# MPU_R5SS1_CORE0_AXIS_MPU_R5SS1_CORE0_AXIS register map
Vendor: Texas Instruments
Peripheral module from a debugger description file (folder AM263).
Registers are 32-bit, read-only, reset 0x0 unless marked. A register's access mark holds for its fields unless they carry their own. Offsets are as the file gives them; lines under a group give offsets from that group; [hi:lo] are bit positions; {n}, {i} and the like mark numbered series; 'fields as' and 'values as' point back to an identical list; <NAME> marks a mode.

## MPU_R5SS1_CORE0_AXIS_MPU_R5SS1_CORE0_AXIS
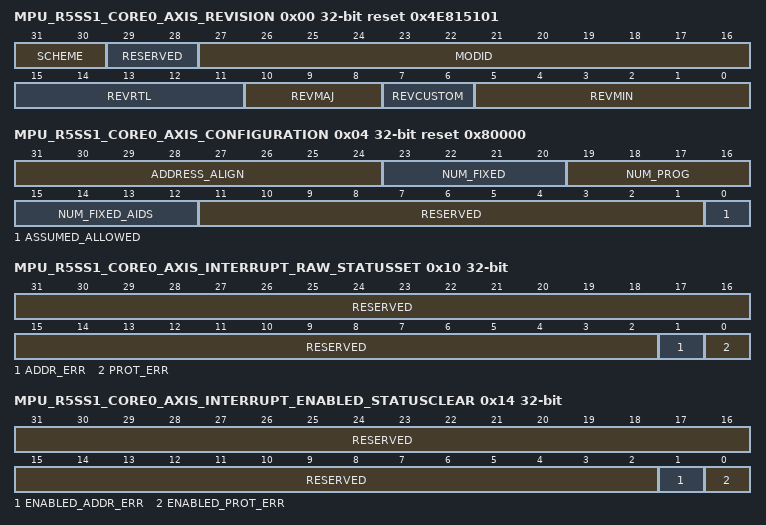
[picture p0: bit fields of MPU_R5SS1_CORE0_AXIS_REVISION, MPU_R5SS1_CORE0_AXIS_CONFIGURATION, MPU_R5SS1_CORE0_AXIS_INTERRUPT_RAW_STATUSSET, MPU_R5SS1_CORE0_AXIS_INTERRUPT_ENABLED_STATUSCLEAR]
0x00 MPU_R5SS1_CORE0_AXIS_REVISION reset 0x4E815101
  [31:30] SCHEME
  [29:28] RESERVED — Always read a s0. Writes have no affect.
  [27:16] MODID — Module ID field.
  [15:11] REVRTL — RTL revision.Will vary depending on release.
  [10:8] REVMAJ — Majo revision.
  [7:6] REVCUSTOM — Custom revision.
  [5:0] REVMIN — Minor revision.
0x04 MPU_R5SS1_CORE0_AXIS_CONFIGURATION reset 0x80000
  [31:24] ADDRESS_ALIGN — Address alignment for range checking.
  [23:20] NUM_FIXED — Number of fixed address ranges Configurable as 0 or 1.
  [19:16] NUM_PROG — Number of programmable address ranges.Value is determined by configuration
  [15:12] NUM_FIXED_AIDS — Number of supported AIDs.0 = no specific AIDs supported (all treated equally)N = PrivIDs from 0 to N-1 supported, others use AIDX
  [11:1] RESERVED — Always read as 0.
  [0] ASSUMED_ALLOWED — Assumed allowed mode. 0 = assumed disallowed, 1 = assumed allowed
0x10 MPU_R5SS1_CORE0_AXIS_INTERRUPT_RAW_STATUSSET access not given
  [31:2] RESERVED ro — Always read as 0.
  [1] ADDR_ERR — Addressing violation error. Raw status is read.Write a 1 to set the status. Writing a 0 has no effect. (access RW W1TOSET)
  [0] PROT_ERR — Protection violation error. Raw status is read. Write a 1 to set the status. Writing a 0 has no effect. (access RW W1TOSET)
0x14 MPU_R5SS1_CORE0_AXIS_INTERRUPT_ENABLED_STATUSCLEAR access not given
  [31:2] RESERVED ro — Always read as 0.
  [1] ENABLED_ADDR_ERR — Addressing violation error. Enabled status is read.Write a 1 to clear the status. Writing a 0 has no effect. (access RW W0TOCLR)
  [0] ENABLED_PROT_ERR — Protection violation error. Enabled status is read. Write a 1 to clear the status. Writing a 0 has no effect. (access RW W0TOCLR)
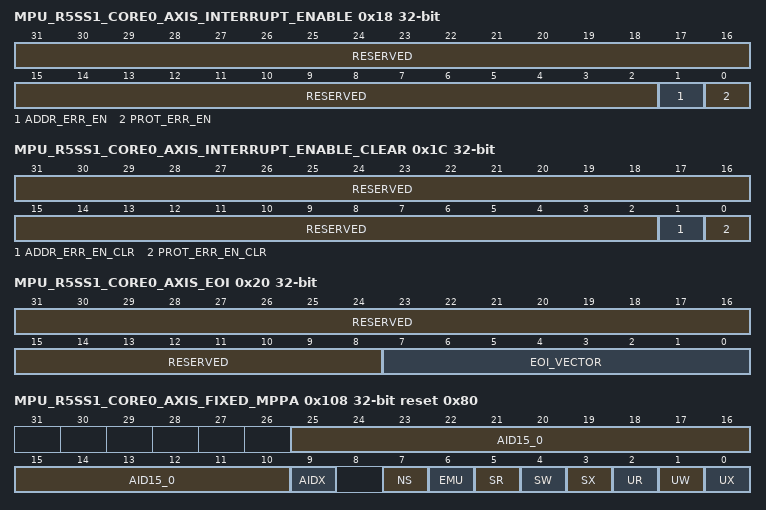
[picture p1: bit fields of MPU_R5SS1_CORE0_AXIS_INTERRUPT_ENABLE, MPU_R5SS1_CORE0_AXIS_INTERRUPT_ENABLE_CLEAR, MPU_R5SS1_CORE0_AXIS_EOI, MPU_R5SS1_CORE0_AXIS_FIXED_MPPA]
0x18 MPU_R5SS1_CORE0_AXIS_INTERRUPT_ENABLE access not given
  [31:2] RESERVED ro — Always read as 0.
  [1] ADDR_ERR_EN — Addressing violation error enable. Write a 1 to set the enable. Writing a 0 has no effect. (access RW W1TOSET)
  [0] PROT_ERR_EN — Protection violation error enable. Write a 1 to set the enable. Writing a 0 has no effect. (access RW W1TOSET)
0x1C MPU_R5SS1_CORE0_AXIS_INTERRUPT_ENABLE_CLEAR access not given
  [31:2] RESERVED ro — Always read as 0.
  [1] ADDR_ERR_EN_CLR — Addressing violation error enable. Write a 1 to clear the enable. Writing a 0 has no effect. (access RW W0TOCLR)
  [0] PROT_ERR_EN_CLR — Protection violation error enable. Write a 1 to clear the enable. Writing a 0 has no effect. (access RW W0TOCLR)
0x20 MPU_R5SS1_CORE0_AXIS_EOI access per field
  [31:8] RESERVED ro — Always read as 0.
  [7:0] EOI_VECTOR rw — EOI vector value.Write this with the interrupt distribution value in the chip. This drives the mpu_eoi_vector output signal.
0x24 MPU_R5SS1_CORE0_AXIS_INTERRUPT_VECTOR
  [31:0] INTR_VEC — Interrupt vector. Reads mpu_intr_vector input signal.
0x100 MPU_R5SS1_CORE0_AXIS_FIXED_START_ADDRESS
  [31:0] START_ADDR — Reserved not used in Design
0x104 MPU_R5SS1_CORE0_AXIS_FIXED_END_ADDRESS
  [31:0] END_ADDR — Reserved not used in Design
0x108 MPU_R5SS1_CORE0_AXIS_FIXED_MPPA reset 0x80
  [25:10] AID15_0 — Reserved not used in Design
  [9] AIDX — Reserved not used in Design
  [7] NS — Reserved not used in Design
  [6] EMU — Reserved not used in Design
  [5] SR — Reserved not used in Design
  [4] SW — Reserved not used in Design
  [3] SX — Reserved not used in Design
  [2] UR — Reserved not used in Design
  [1] UW — Reserved not used in Design
  [0] UX — Reserved not used in Design
{0x1F0+0x10*i} MPU_R5SS1_CORE0_AXIS_PROGRAMMABLE_{i}_START_ADDRESS rw (i=1..8)
  [31:0] START_ADDR — Start address for range N. Defaults to input signal value.
{0x1F4+0x10*i} MPU_R5SS1_CORE0_AXIS_PROGRAMMABLE_{i}_END_ADDRESS rw (i=1..8)
  [31:0] END_ADDR — End address for range N. Defaults to input signal value.
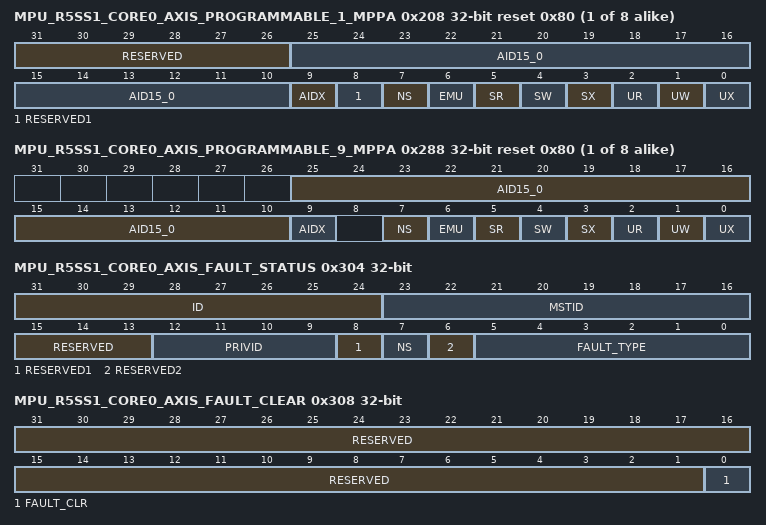
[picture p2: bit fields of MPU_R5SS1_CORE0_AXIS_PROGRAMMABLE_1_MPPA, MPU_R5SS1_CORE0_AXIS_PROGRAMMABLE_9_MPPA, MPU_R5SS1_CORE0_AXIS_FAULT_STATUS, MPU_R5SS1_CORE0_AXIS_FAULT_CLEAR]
{0x1F8+0x10*i} MPU_R5SS1_CORE0_AXIS_PROGRAMMABLE_{i}_MPPA access per field reset 0x80 (i=1..8)
  [31:26] RESERVED ro — Always read as 0.
  [25:10] AID15_0 rw — AIDs checked for this region. Defaults to input value.0 = AID is not checked for these permissions.1 = AID is checked for these permissions.
  [9] AIDX rw — Additional AIDs checked. Defaults to input value.
  [8] RESERVED1 ro — Always read as 0.
  [7] NS rw — Non-secure permission. Defaults to input value.
  [6] EMU rw — Debug permission. Defaults to input value.
  [5] SR rw — Supervisor read permission. Defaults to input value.
  [4] SW rw — Supervisor write permission. Defaults to input value.
  [3] SX rw — Supervisor executable permission. Defaults to input value.
  [2] UR rw — User read permission. Defaults to input value.
  [1] UW rw — User write permission. Defaults to input value.
  [0] UX rw — User executable permission. Defaults to input value.
{0x1F0+0x10*i} MPU_R5SS1_CORE0_AXIS_PROGRAMMABLE_{i}_START_ADDRESS (i=9..16)
  [31:0] START_ADDR — Reserved not used in Design
{0x1F4+0x10*i} MPU_R5SS1_CORE0_AXIS_PROGRAMMABLE_{i}_END_ADDRESS (i=9..16)
  [31:0] END_ADDR — Reserved not used in Design
{0x1F8+0x10*i} MPU_R5SS1_CORE0_AXIS_PROGRAMMABLE_{i}_MPPA reset 0x80 (i=9..16)
  fields as MPU_R5SS1_CORE0_AXIS_FIXED_MPPA
0x300 MPU_R5SS1_CORE0_AXIS_FAULT_ADDRESS
  [31:0] FAULT_ADDR — Fault address.
0x304 MPU_R5SS1_CORE0_AXIS_FAULT_STATUS
  [31:24] ID — Transfer ID
  [23:16] MSTID — Master ID.
  [15:13] RESERVED — Always read as 0.
  [12:9] PRIVID — Privilege ID.
  [8] RESERVED1 — Always read as 0.
  [7] NS — Non-secure access.
  [6] RESERVED2 — Always read as 0.
  [5:0] FAULT_TYPE — Fault type.100000 = supervisor read fault010000 = supervisor write fault001000 = supervisor execute fault000100 = user read fault000010 = user write fault000001 = user execute fault111111 = relaxed cache linefill fault010010 = relaxed cache writeback fault000000 = no fault
0x308 MPU_R5SS1_CORE0_AXIS_FAULT_CLEAR access per field
  [31:1] RESERVED ro — Always read as 0.
  [0] FAULT_CLR wo — Fault clear. Writing a 1 clears the current fault. Writing a0 has no effect.
